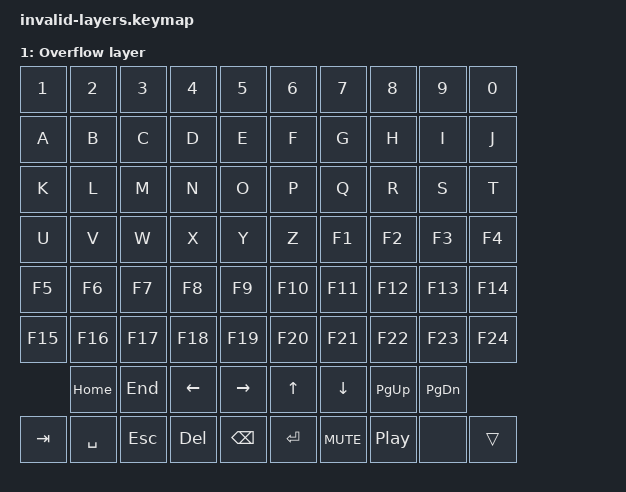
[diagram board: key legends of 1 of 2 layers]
    / {
    keymap {
        compatible = "zmk,keymap";

        short_layer {
            display-name = "Short layer";
            bindings = <
                &kp A &kp B &kp C &kp D &kp E &kp F
            >;
        };

        overflow_layer {
            display-name = "Overflow layer";
            bindings = <
                &kp N1 &kp N2 &kp N3 &kp N4 &kp N5 &kp N6 &kp N7 &kp N8 &kp N9 &kp N0
                &kp A &kp B &kp C &kp D &kp E &kp F &kp G &kp H &kp I &kp J
                &kp K &kp L &kp M &kp N &kp O &kp P &kp Q &kp R &kp S &kp T
                &kp U &kp V &kp W &kp X &kp Y &kp Z &kp F1 &kp F2 &kp F3 &kp F4
                &kp F5 &kp F6 &kp F7 &kp F8 &kp F9 &kp F10 &kp F11 &kp F12 &kp F13 &kp F14
                &kp F15 &kp F16 &kp F17 &kp F18 &kp F19 &kp F20 &kp F21 &kp F22 &kp F23 &kp F24
                &kp HOME &kp END &kp LEFT &kp RIGHT &kp UP &kp DOWN &kp PAGE_UP &kp PAGE_DOWN
                &kp TAB &kp SPACE &kp ESCAPE &kp DELETE &kp BACKSPACE &kp ENTER &kp C_MUTE &kp C_PLAY_PAUSE &none &trans
            >;
        };
    };
};
